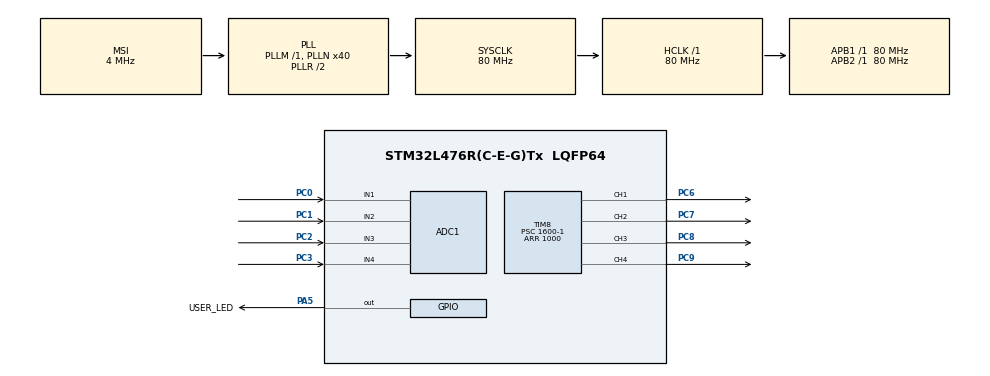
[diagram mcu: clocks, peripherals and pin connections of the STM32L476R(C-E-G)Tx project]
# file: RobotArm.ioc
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ADC1.Channel-0\#ChannelRegularConversion=ADC_CHANNEL_1
ADC1.Channel-4\#ChannelRegularConversion=ADC_CHANNEL_2
ADC1.Channel-5\#ChannelRegularConversion=ADC_CHANNEL_3
ADC1.Channel-6\#ChannelRegularConversion=ADC_CHANNEL_4
ADC1.ContinuousConvMode=ENABLE
ADC1.NbrOfConversion=4
ADC1.NbrOfConversionFlag=1
ADC1.OffsetNumber-0\#ChannelRegularConversion=ADC_OFFSET_NONE
ADC1.OffsetNumber-4\#ChannelRegularConversion=ADC_OFFSET_NONE
ADC1.OffsetNumber-5\#ChannelRegularConversion=ADC_OFFSET_NONE
ADC1.OffsetNumber-6\#ChannelRegularConversion=ADC_OFFSET_NONE
ADC1.Rank-0\#ChannelRegularConversion=1
ADC1.Rank-4\#ChannelRegularConversion=2
ADC1.Rank-5\#ChannelRegularConversion=3
ADC1.Rank-6\#ChannelRegularConversion=4
ADC1.SamplingTime-0\#ChannelRegularConversion=ADC_SAMPLETIME_2CYCLES_5
ADC1.SamplingTime-4\#ChannelRegularConversion=ADC_SAMPLETIME_2CYCLES_5
ADC1.SamplingTime-5\#ChannelRegularConversion=ADC_SAMPLETIME_2CYCLES_5
ADC1.SamplingTime-6\#ChannelRegularConversion=ADC_SAMPLETIME_2CYCLES_5
ADC1.master=1
Dma.ADC1.0.Direction=DMA_PERIPH_TO_MEMORY
Dma.ADC1.0.Instance=DMA2_Channel3
Dma.ADC1.0.MemDataAlignment=DMA_MDATAALIGN_WORD
Dma.ADC1.0.MemInc=DMA_MINC_ENABLE
Dma.ADC1.0.Mode=DMA_CIRCULAR
Dma.ADC1.0.PeriphDataAlignment=DMA_PDATAALIGN_WORD
Dma.ADC1.0.PeriphInc=DMA_PINC_DISABLE
Dma.ADC1.0.Priority=DMA_PRIORITY_LOW
Dma.Request0=ADC1
Mcu.Family=STM32L4
Mcu.Name=STM32L476R(C-E-G)Tx
Mcu.Package=LQFP64
NVIC.DMA2_Channel3_IRQn=true\:0\:0\:false\:false\:true\:false\:true
NVIC.PriorityGroup=NVIC_PRIORITYGROUP_4
NVIC.TIM6_DAC_IRQn=true\:2\:0\:true\:false\:true\:true\:true
PA5.GPIO_Label=USER_LED
PA5.Signal=GPIO_Output
PC0.Signal=ADCx_IN1
PC1.Signal=ADCx_IN2
PC2.Signal=ADCx_IN3
PC3.Signal=ADCx_IN4
PC6.Signal=S_TIM8_CH1
PC7.Signal=S_TIM8_CH2
PC8.Signal=S_TIM8_CH3
PC9.Signal=S_TIM8_CH4
ProjectManager.HeapSize=0x200
ProjectManager.StackSize=0x400
ProjectManager.TargetToolchain=MDK-ARM V5
RCC.ADCFreq_Value=32000000
RCC.AHBFreq_Value=80000000
RCC.APB1Freq_Value=80000000
RCC.APB1TimFreq_Value=80000000
RCC.APB2Freq_Value=80000000
RCC.APB2TimFreq_Value=80000000
RCC.CortexFreq_Value=80000000
RCC.HCLKFreq_Value=80000000
RCC.HSE_VALUE=8000000
RCC.HSI_VALUE=16000000
RCC.LSE_VALUE=32768
RCC.MSI_VALUE=4000000
RCC.PLLN=40
RCC.PLLSAI1N=16
RCC.SYSCLKFreq_VALUE=80000000
RCC.SYSCLKSource=RCC_SYSCLKSOURCE_PLLCLK
RCC.USBFreq_Value=32000000
RCC.VCOOutputFreq_Value=160000000
SH.ADCx_IN1.0=ADC1_IN1,IN1-Single-Ended
SH.ADCx_IN2.0=ADC1_IN2,IN2-Single-Ended
SH.ADCx_IN3.0=ADC1_IN3,IN3-Single-Ended
SH.ADCx_IN4.0=ADC1_IN4,IN4-Single-Ended
SH.S_TIM8_CH1.0=TIM8_CH1,PWM Generation1 CH1
SH.S_TIM8_CH2.0=TIM8_CH2,PWM Generation2 CH2
SH.S_TIM8_CH3.0=TIM8_CH3,PWM Generation3 CH3
SH.S_TIM8_CH4.0=TIM8_CH4,PWM Generation4 CH4
TIM6.Period=1000-1
TIM6.Prescaler=80-1
TIM8.Channel-PWM\ Generation1\ CH1=TIM_CHANNEL_1
TIM8.Channel-PWM\ Generation2\ CH2=TIM_CHANNEL_2
TIM8.Channel-PWM\ Generation3\ CH3=TIM_CHANNEL_3
TIM8.Channel-PWM\ Generation4\ CH4=TIM_CHANNEL_4
TIM8.Period=1000
TIM8.Prescaler=1600-1
VP_TIM6_VS_ClockSourceINT.Mode=Enable_Timer
VP_TIM8_VS_ClockSourceINT.Mode=Internal
board=custom

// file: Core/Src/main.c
/* USER CODE BEGIN Header */
/**
  ******************************************************************************
  * @file           : main.c
  * @brief          : Main program body
  ******************************************************************************
  * @attention
  *
  * <h2><center>&copy; Copyright (c) 2020 STMicroelectronics.
  * All rights reserved.</center></h2>
  *
  * This software component is licensed by ST under BSD 3-Clause license,
  * the "License"; You may not use this file except in compliance with the
  * License. You may obtain a copy of the License at:
  *                        opensource.org/licenses/BSD-3-Clause
  *
  ******************************************************************************
  */
/* USER CODE END Header */
#include "main.h"

/* USER CODE BEGIN Includes */
#include "robotarm.h"
/* USER CODE END Includes */

ADC_HandleTypeDef hadc1;
DMA_HandleTypeDef hdma_adc1;

TIM_HandleTypeDef htim6;
TIM_HandleTypeDef htim8;

/* USER CODE BEGIN PV */
extern uint32_t adc_val[4];

/* USER CODE END PV */

void SystemClock_Config(void);
static void MX_GPIO_Init(void);
static void MX_DMA_Init(void);
static void MX_ADC1_Init(void);
static void MX_TIM6_Init(void);
static void MX_TIM8_Init(void);

int main(void)
{

  /* MCU Configuration--------------------------------------------------------*/

  /* Reset of all peripherals, Initializes the Flash interface and the Systick. */
  HAL_Init();

  /* Configure the system clock */
  SystemClock_Config();

  /* Initialize all configured peripherals */
  MX_GPIO_Init();
  MX_DMA_Init();
  MX_ADC1_Init();
  MX_TIM6_Init();
  MX_TIM8_Init();
  /* USER CODE BEGIN 2 */
	HAL_TIM_PWM_Start(&htim8, TIM_CHANNEL_1);
	HAL_TIM_PWM_Start(&htim8, TIM_CHANNEL_2);
	HAL_TIM_PWM_Start(&htim8, TIM_CHANNEL_3);
	HAL_TIM_PWM_Start(&htim8, TIM_CHANNEL_4);

	HAL_ADC_Start_DMA(&hadc1, adc_val, 4);
	HandlerServosPot();

  /* USER CODE END 2 */

  /* Infinite loop */
  while (1)
  {

    /* USER CODE BEGIN 3 */

//		MoveServoGripper(50, 70);
//		HAL_Delay(1000);

  }
  /* USER CODE END 3 */
}

void SystemClock_Config(void)
{
  RCC_OscInitTypeDef RCC_OscInitStruct = {0};
  RCC_ClkInitTypeDef RCC_ClkInitStruct = {0};
  RCC_PeriphCLKInitTypeDef PeriphClkInit = {0};

  /** Initializes the RCC Oscillators according to the specified parameters
  * in the RCC_OscInitTypeDef structure.
  */
  RCC_OscInitStruct.OscillatorType = RCC_OSCILLATORTYPE_MSI;
  RCC_OscInitStruct.MSIState = RCC_MSI_ON;
  RCC_OscInitStruct.MSICalibrationValue = 0;
  RCC_OscInitStruct.MSIClockRange = RCC_MSIRANGE_6;
  RCC_OscInitStruct.PLL.PLLState = RCC_PLL_ON;
  RCC_OscInitStruct.PLL.PLLSource = RCC_PLLSOURCE_MSI;
  RCC_OscInitStruct.PLL.PLLM = 1;
  RCC_OscInitStruct.PLL.PLLN = 40;
  RCC_OscInitStruct.PLL.PLLP = RCC_PLLP_DIV7;
  RCC_OscInitStruct.PLL.PLLQ = RCC_PLLQ_DIV2;
  RCC_OscInitStruct.PLL.PLLR = RCC_PLLR_DIV2;
  if (HAL_RCC_OscConfig(&RCC_OscInitStruct) != HAL_OK)
  {
    Error_Handler();
  }
  /** Initializes the CPU, AHB and APB buses clocks
  */
  RCC_ClkInitStruct.ClockType = RCC_CLOCKTYPE_HCLK|RCC_CLOCKTYPE_SYSCLK
                              |RCC_CLOCKTYPE_PCLK1|RCC_CLOCKTYPE_PCLK2;
  RCC_ClkInitStruct.SYSCLKSource = RCC_SYSCLKSOURCE_PLLCLK;
  RCC_ClkInitStruct.AHBCLKDivider = RCC_SYSCLK_DIV1;
  RCC_ClkInitStruct.APB1CLKDivider = RCC_HCLK_DIV1;
  RCC_ClkInitStruct.APB2CLKDivider = RCC_HCLK_DIV1;

  if (HAL_RCC_ClockConfig(&RCC_ClkInitStruct, FLASH_LATENCY_4) != HAL_OK)
  {
    Error_Handler();
  }
  PeriphClkInit.PeriphClockSelection = RCC_PERIPHCLK_ADC;
  PeriphClkInit.AdcClockSelection = RCC_ADCCLKSOURCE_PLLSAI1;
  PeriphClkInit.PLLSAI1.PLLSAI1Source = RCC_PLLSOURCE_MSI;
  PeriphClkInit.PLLSAI1.PLLSAI1M = 1;
  PeriphClkInit.PLLSAI1.PLLSAI1N = 16;
  PeriphClkInit.PLLSAI1.PLLSAI1P = RCC_PLLP_DIV7;
  PeriphClkInit.PLLSAI1.PLLSAI1Q = RCC_PLLQ_DIV2;
  PeriphClkInit.PLLSAI1.PLLSAI1R = RCC_PLLR_DIV2;
  PeriphClkInit.PLLSAI1.PLLSAI1ClockOut = RCC_PLLSAI1_ADC1CLK;
  if (HAL_RCCEx_PeriphCLKConfig(&PeriphClkInit) != HAL_OK)
  {
    Error_Handler();
  }
  /** Configure the main internal regulator output voltage
  */
  if (HAL_PWREx_ControlVoltageScaling(PWR_REGULATOR_VOLTAGE_SCALE1) != HAL_OK)
  {
    Error_Handler();
  }
}

static void MX_ADC1_Init(void)
{

  ADC_MultiModeTypeDef multimode = {0};
  ADC_ChannelConfTypeDef sConfig = {0};

  /** Common config
  */
  hadc1.Instance = ADC1;
  hadc1.Init.ClockPrescaler = ADC_CLOCK_ASYNC_DIV1;
  hadc1.Init.Resolution = ADC_RESOLUTION_12B;
  hadc1.Init.DataAlign = ADC_DATAALIGN_RIGHT;
  hadc1.Init.ScanConvMode = ADC_SCAN_ENABLE;
  hadc1.Init.EOCSelection = ADC_EOC_SINGLE_CONV;
  hadc1.Init.LowPowerAutoWait = DISABLE;
  hadc1.Init.ContinuousConvMode = ENABLE;
  hadc1.Init.NbrOfConversion = 4;
  hadc1.Init.DiscontinuousConvMode = DISABLE;
  hadc1.Init.ExternalTrigConv = ADC_SOFTWARE_START;
  hadc1.Init.ExternalTrigConvEdge = ADC_EXTERNALTRIGCONVEDGE_NONE;
  hadc1.Init.DMAContinuousRequests = DISABLE;
  hadc1.Init.Overrun = ADC_OVR_DATA_PRESERVED;
  hadc1.Init.OversamplingMode = DISABLE;
  if (HAL_ADC_Init(&hadc1) != HAL_OK)
  {
    Error_Handler();
  }
  /** Configure the ADC multi-mode
  */
  multimode.Mode = ADC_MODE_INDEPENDENT;
  if (HAL_ADCEx_MultiModeConfigChannel(&hadc1, &multimode) != HAL_OK)
  {
    Error_Handler();
  }
  /** Configure Regular Channel
  */
  sConfig.Channel = ADC_CHANNEL_1;
  sConfig.Rank = ADC_REGULAR_RANK_1;
  sConfig.SamplingTime = ADC_SAMPLETIME_2CYCLES_5;
  sConfig.SingleDiff = ADC_SINGLE_ENDED;
  sConfig.OffsetNumber = ADC_OFFSET_NONE;
  sConfig.Offset = 0;
  if (HAL_ADC_ConfigChannel(&hadc1, &sConfig) != HAL_OK)
  {
    Error_Handler();
  }
  /** Configure Regular Channel
  */
  sConfig.Channel = ADC_CHANNEL_2;
  sConfig.Rank = ADC_REGULAR_RANK_2;
  if (HAL_ADC_ConfigChannel(&hadc1, &sConfig) != HAL_OK)
  {
    Error_Handler();
  }
  /** Configure Regular Channel
  */
  sConfig.Channel = ADC_CHANNEL_3;
  sConfig.Rank = ADC_REGULAR_RANK_3;
  if (HAL_ADC_ConfigChannel(&hadc1, &sConfig) != HAL_OK)
  {
    Error_Handler();
  }
  /** Configure Regular Channel
  */
  sConfig.Channel = ADC_CHANNEL_4;
  sConfig.Rank = ADC_REGULAR_RANK_4;
  if (HAL_ADC_ConfigChannel(&hadc1, &sConfig) != HAL_OK)
  {
    Error_Handler();
  }

}

static void MX_TIM6_Init(void)
{

  TIM_MasterConfigTypeDef sMasterConfig = {0};

  /* USER CODE BEGIN TIM6_Init 1 */
	HAL_NVIC_EnableIRQ(TIM6_IRQn);
	__HAL_RCC_TIM6_CLK_ENABLE();
  /* USER CODE END TIM6_Init 1 */
  htim6.Instance = TIM6;
  htim6.Init.Prescaler = 80-1;
  htim6.Init.CounterMode = TIM_COUNTERMODE_UP;
  htim6.Init.Period = 1000-1;
  htim6.Init.AutoReloadPreload = TIM_AUTORELOAD_PRELOAD_DISABLE;
  if (HAL_TIM_Base_Init(&htim6) != HAL_OK)
  {
    Error_Handler();
  }
  sMasterConfig.MasterOutputTrigger = TIM_TRGO_RESET;
  sMasterConfig.MasterSlaveMode = TIM_MASTERSLAVEMODE_DISABLE;
  if (HAL_TIMEx_MasterConfigSynchronization(&htim6, &sMasterConfig) != HAL_OK)
  {
    Error_Handler();
  }
  /* USER CODE BEGIN TIM6_Init 2 */
	HAL_TIM_Base_Init(&htim6);
	HAL_TIM_Base_Start_IT(&htim6);
  /* USER CODE END TIM6_Init 2 */

}

static void MX_TIM8_Init(void)
{

  TIM_ClockConfigTypeDef sClockSourceConfig = {0};
  TIM_MasterConfigTypeDef sMasterConfig = {0};
  TIM_OC_InitTypeDef sConfigOC = {0};
  TIM_BreakDeadTimeConfigTypeDef sBreakDeadTimeConfig = {0};

  htim8.Instance = TIM8;
  htim8.Init.Prescaler = 1600-1;
  htim8.Init.CounterMode = TIM_COUNTERMODE_UP;
  htim8.Init.Period = 1000;
  htim8.Init.ClockDivision = TIM_CLOCKDIVISION_DIV1;
  htim8.Init.RepetitionCounter = 0;
  htim8.Init.AutoReloadPreload = TIM_AUTORELOAD_PRELOAD_DISABLE;
  if (HAL_TIM_Base_Init(&htim8) != HAL_OK)
  {
    Error_Handler();
  }
  sClockSourceConfig.ClockSource = TIM_CLOCKSOURCE_INTERNAL;
  if (HAL_TIM_ConfigClockSource(&htim8, &sClockSourceConfig) != HAL_OK)
  {
    Error_Handler();
  }
  if (HAL_TIM_PWM_Init(&htim8) != HAL_OK)
  {
    Error_Handler();
  }
  sMasterConfig.MasterOutputTrigger = TIM_TRGO_RESET;
  sMasterConfig.MasterOutputTrigger2 = TIM_TRGO2_RESET;
  sMasterConfig.MasterSlaveMode = TIM_MASTERSLAVEMODE_DISABLE;
  if (HAL_TIMEx_MasterConfigSynchronization(&htim8, &sMasterConfig) != HAL_OK)
  {
    Error_Handler();
  }
  sConfigOC.OCMode = TIM_OCMODE_PWM1;
  sConfigOC.Pulse = 0;
  sConfigOC.OCPolarity = TIM_OCPOLARITY_HIGH;
  sConfigOC.OCNPolarity = TIM_OCNPOLARITY_HIGH;
  sConfigOC.OCFastMode = TIM_OCFAST_DISABLE;
  sConfigOC.OCIdleState = TIM_OCIDLESTATE_RESET;
  sConfigOC.OCNIdleState = TIM_OCNIDLESTATE_RESET;
  if (HAL_TIM_PWM_ConfigChannel(&htim8, &sConfigOC, TIM_CHANNEL_1) != HAL_OK)
  {
    Error_Handler();
  }
  if (HAL_TIM_PWM_ConfigChannel(&htim8, &sConfigOC, TIM_CHANNEL_2) != HAL_OK)
  {
    Error_Handler();
  }
  if (HAL_TIM_PWM_ConfigChannel(&htim8, &sConfigOC, TIM_CHANNEL_3) != HAL_OK)
  {
    Error_Handler();
  }
  if (HAL_TIM_PWM_ConfigChannel(&htim8, &sConfigOC, TIM_CHANNEL_4) != HAL_OK)
  {
    Error_Handler();
  }
  sBreakDeadTimeConfig.OffStateRunMode = TIM_OSSR_DISABLE;
  sBreakDeadTimeConfig.OffStateIDLEMode = TIM_OSSI_DISABLE;
  sBreakDeadTimeConfig.LockLevel = TIM_LOCKLEVEL_OFF;
  sBreakDeadTimeConfig.DeadTime = 0;
  sBreakDeadTimeConfig.BreakState = TIM_BREAK_DISABLE;
  sBreakDeadTimeConfig.BreakPolarity = TIM_BREAKPOLARITY_HIGH;
  sBreakDeadTimeConfig.BreakFilter = 0;
  sBreakDeadTimeConfig.Break2State = TIM_BREAK2_DISABLE;
  sBreakDeadTimeConfig.Break2Polarity = TIM_BREAK2POLARITY_HIGH;
  sBreakDeadTimeConfig.Break2Filter = 0;
  sBreakDeadTimeConfig.AutomaticOutput = TIM_AUTOMATICOUTPUT_DISABLE;
  if (HAL_TIMEx_ConfigBreakDeadTime(&htim8, &sBreakDeadTimeConfig) != HAL_OK)
  {
    Error_Handler();
  }
  HAL_TIM_MspPostInit(&htim8);

}

static void MX_DMA_Init(void)
{

  /* DMA controller clock enable */
  __HAL_RCC_DMA2_CLK_ENABLE();

  /* DMA interrupt init */
  /* DMA2_Channel3_IRQn interrupt configuration */
  HAL_NVIC_SetPriority(DMA2_Channel3_IRQn, 0, 0);
  HAL_NVIC_EnableIRQ(DMA2_Channel3_IRQn);

}

static void MX_GPIO_Init(void)
{
  GPIO_InitTypeDef GPIO_InitStruct = {0};

  /* GPIO Ports Clock Enable */
  __HAL_RCC_GPIOC_CLK_ENABLE();
  __HAL_RCC_GPIOA_CLK_ENABLE();

  /*Configure GPIO pin Output Level */
  HAL_GPIO_WritePin(USER_LED_GPIO_Port, USER_LED_Pin, GPIO_PIN_RESET);

  /*Configure GPIO pin : USER_LED_Pin */
  GPIO_InitStruct.Pin = USER_LED_Pin;
  GPIO_InitStruct.Mode = GPIO_MODE_OUTPUT_PP;
  GPIO_InitStruct.Pull = GPIO_NOPULL;
  GPIO_InitStruct.Speed = GPIO_SPEED_FREQ_LOW;
  HAL_GPIO_Init(USER_LED_GPIO_Port, &GPIO_InitStruct);

}

void Error_Handler(void)
{
}

/************************ (C) COPYRIGHT STMicroelectronics *****END OF FILE****/
